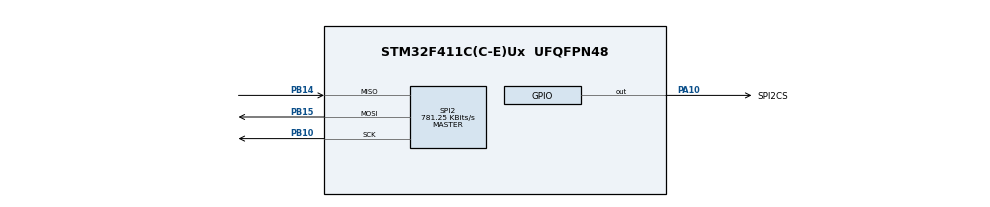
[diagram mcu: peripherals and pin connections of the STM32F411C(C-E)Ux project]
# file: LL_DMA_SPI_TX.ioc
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Mcu.Family=STM32F4
RCC.PLLSourceVirtual=RCC_PLLSOURCE_HSE
Dma.SPI2_TX.0.MemInc=DMA_MINC_ENABLE
RCC.CortexFreq_Value=100000000
SPI2.VirtualType=VM_MASTER
PB10.Mode=Full_Duplex_Master
PH1\ -\ OSC_OUT.Mode=HSE-External-Oscillator
RCC.APB1CLKDivider=RCC_HCLK_DIV2
NVIC.DMA1_Stream4_IRQn=true\:0\:0\:false\:false\:true\:false\:true
PB15.Signal=SPI2_MOSI
Dma.SPI2_TX.0.Instance=DMA1_Stream4
RCC.SYSCLKSource=RCC_SYSCLKSOURCE_PLLCLK
ProjectManager.StackSize=0x400
Dma.SPI2_TX.0.MemDataAlignment=DMA_MDATAALIGN_HALFWORD
PA13.Signal=SYS_JTMS-SWDIO
PH0\ -\ OSC_IN.Mode=HSE-External-Oscillator
SPI2.CLKPolarity=SPI_POLARITY_HIGH
PH0\ -\ OSC_IN.Signal=RCC_OSC_IN
ProjectManager.TargetToolchain=STM32CubeIDE
PA10.PinState=GPIO_PIN_SET
RCC.HCLKFreq_Value=100000000
RCC.APB2TimFreq_Value=100000000
Dma.SPI2_TX.0.Mode=DMA_NORMAL
RCC.LSE_VALUE=32768
RCC.AHBFreq_Value=100000000
SPI2.BaudRatePrescaler=SPI_BAUDRATEPRESCALER_64
PB10.Signal=SPI2_SCK
PB14.Signal=SPI2_MISO
RCC.HSE_VALUE=25000000
PH1\ -\ OSC_OUT.Signal=RCC_OSC_OUT
board=custom
RCC.VCOOutputFreq_Value=200000000
PB15.Mode=Full_Duplex_Master
RCC.APB2Freq_Value=100000000
PA14.Mode=Serial_Wire
Dma.SPI2_TX.0.PeriphDataAlignment=DMA_PDATAALIGN_HALFWORD
PB14.Mode=Full_Duplex_Master
PA10.GPIO_Label=SPI2CS
SPI2.CalculateBaudRate=781.25 KBits/s
NVIC.SPI2_IRQn=true\:0\:0\:false\:false\:true\:true\:true
PA13.Mode=Serial_Wire
Mcu.Name=STM32F411C(C-E)Ux
Dma.SPI2_TX.0.FIFOMode=DMA_FIFOMODE_DISABLE
RCC.48MHZClocksFreq_Value=50000000
Dma.SPI2_TX.0.Priority=DMA_PRIORITY_MEDIUM
RCC.SYSCLKFreq_VALUE=100000000
Mcu.Package=UFQFPN48
SPI2.Mode=SPI_MODE_MASTER
PA10.Signal=GPIO_Output
PA14.Signal=SYS_JTCK-SWCLK
ProjectManager.HeapSize=0x200
SPI2.CLKPhase=SPI_PHASE_2EDGE
RCC.HSI_VALUE=16000000
Dma.SPI2_TX.0.PeriphInc=DMA_PINC_DISABLE
NVIC.PriorityGroup=NVIC_PRIORITYGROUP_4
RCC.PLLM=12
RCC.PLLN=96
RCC.APB1TimFreq_Value=100000000
SPI2.DataSize=SPI_DATASIZE_16BIT
SPI2.Direction=SPI_DIRECTION_2LINES
Dma.SPI2_TX.0.Direction=DMA_MEMORY_TO_PERIPH
RCC.APB1Freq_Value=50000000
Dma.Request0=SPI2_TX

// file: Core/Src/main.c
/* USER CODE BEGIN Header */
/**
  ******************************************************************************
  * @file           : main.c
  * @brief          : Main program body
  ******************************************************************************
  * @attention
  *
  * <h2><center>&copy; Copyright (c) 2021 STMicroelectronics.
  * All rights reserved.</center></h2>
  *
  * This software component is licensed by ST under BSD 3-Clause license,
  * the "License"; You may not use this file except in compliance with the
  * License. You may obtain a copy of the License at:
  *                        opensource.org/licenses/BSD-3-Clause
  *
  ******************************************************************************
  */
/* USER CODE END Header */
#include "main.h"
#include "dma.h"
#include "spi.h"
#include "gpio.h"

void SystemClock_Config(void);

/* USER CODE BEGIN 0 */
uint16_t mainBuff[B_SIZE]={1,2,3,4,5,6,7,8,9,10,11,12,13,14,15,16,17,18,19,20,1,2,3,4,5,6,7,8,9,10,11,12,13,14,15,16,17,18,19,20,1,2,3,4,5,6,7,8,9,10,11,12,13,14,15,16,17,18,19,20,48,49,50,51};
/* USER CODE END 0 */

int main(void)
{

  /* MCU Configuration--------------------------------------------------------*/

  /* Reset of all peripherals, Initializes the Flash interface and the Systick. */

  LL_APB2_GRP1_EnableClock(LL_APB2_GRP1_PERIPH_SYSCFG);
  LL_APB1_GRP1_EnableClock(LL_APB1_GRP1_PERIPH_PWR);

  NVIC_SetPriorityGrouping(NVIC_PRIORITYGROUP_4);

  /* System interrupt init*/

  /* Configure the system clock */
  SystemClock_Config();

  /* Initialize all configured peripherals */
  MX_GPIO_Init();
  MX_DMA_Init();
  MX_SPI2_Init();
  /* USER CODE BEGIN 2 */
  LL_SPI_Enable(SPI2);
  dma_init();
  /* USER CODE END 2 */

  /* Infinite loop */
  /* USER CODE BEGIN WHILE */
  while (1)
  {
	 if(LL_SPI_IsActiveFlag_TXE(SPI2)) dma_init();
	 LL_mDelay(10);
    /* USER CODE END WHILE */

  }
}

void SystemClock_Config(void)
{
  LL_FLASH_SetLatency(LL_FLASH_LATENCY_3);
  while(LL_FLASH_GetLatency()!= LL_FLASH_LATENCY_3)
  {
  }
  LL_PWR_SetRegulVoltageScaling(LL_PWR_REGU_VOLTAGE_SCALE1);
  LL_RCC_HSE_Enable();

   /* Wait till HSE is ready */
  while(LL_RCC_HSE_IsReady() != 1)
  {

  }
  LL_RCC_PLL_ConfigDomain_SYS(LL_RCC_PLLSOURCE_HSE, LL_RCC_PLLM_DIV_12, 96, LL_RCC_PLLP_DIV_2);
  LL_RCC_PLL_Enable();

   /* Wait till PLL is ready */
  while(LL_RCC_PLL_IsReady() != 1)
  {

  }
  LL_RCC_SetAHBPrescaler(LL_RCC_SYSCLK_DIV_1);
  LL_RCC_SetAPB1Prescaler(LL_RCC_APB1_DIV_2);
  LL_RCC_SetAPB2Prescaler(LL_RCC_APB2_DIV_1);
  LL_RCC_SetSysClkSource(LL_RCC_SYS_CLKSOURCE_PLL);

   /* Wait till System clock is ready */
  while(LL_RCC_GetSysClkSource() != LL_RCC_SYS_CLKSOURCE_STATUS_PLL)
  {

  }
  LL_Init1msTick(100000000);
  LL_SetSystemCoreClock(100000000);
  LL_RCC_SetTIMPrescaler(LL_RCC_TIM_PRESCALER_TWICE);
}

void Error_Handler(void)
{
  __disable_irq();
  while (1)
  {
  }
}

/************************ (C) COPYRIGHT STMicroelectronics *****END OF FILE****/
